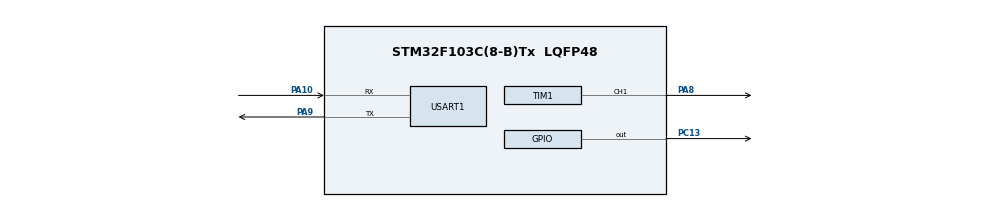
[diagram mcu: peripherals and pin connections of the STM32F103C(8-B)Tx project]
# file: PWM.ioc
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Mcu.Family=STM32F1
Mcu.Name=STM32F103C(8-B)Tx
Mcu.Package=LQFP48
NVIC.PriorityGroup=NVIC_PRIORITYGROUP_4
PA10.Mode=Asynchronous
PA10.Signal=USART1_RX
PA13.Mode=Serial_Wire
PA13.Signal=SYS_JTMS-SWDIO
PA14.Mode=Serial_Wire
PA14.Signal=SYS_JTCK-SWCLK
PA8.Signal=S_TIM1_CH1
PA9.Mode=Asynchronous
PA9.Signal=USART1_TX
PC13-TAMPER-RTC.GPIO_ModeDefaultOutputPP=GPIO_MODE_OUTPUT_OD
PC13-TAMPER-RTC.PinState=GPIO_PIN_SET
PC13-TAMPER-RTC.Signal=GPIO_Output
ProjectManager.HeapSize=0x200
ProjectManager.StackSize=0x400
ProjectManager.TargetToolchain=MDK-ARM V5.32
RCC.APB1Freq_Value=8000000
RCC.APB2Freq_Value=8000000
SH.S_TIM1_CH1.0=TIM1_CH1,PWM Generation1 CH1
TIM1.AutoReloadPreload=TIM_AUTORELOAD_PRELOAD_ENABLE
TIM1.Channel-PWM\ Generation1\ CH1=TIM_CHANNEL_1
TIM1.OCFastMode_PWM-PWM\ Generation1\ CH1=TIM_OCFAST_DISABLE
TIM1.OCMode_PWM-PWM\ Generation1\ CH1=TIM_OCMODE_PWM1
TIM1.OCPolarity_1=TIM_OCPOLARITY_HIGH
TIM1.Period=19999
TIM1.Prescaler=7
TIM1.Pulse-PWM\ Generation1\ CH1=1500
USART1.VirtualMode=VM_ASYNC
VP_TIM1_VS_ClockSourceINT.Mode=Internal
board=custom

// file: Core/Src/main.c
/* USER CODE BEGIN Header */
/**
  ******************************************************************************
  * @file           : main.c
  * @brief          : Main program body
  ******************************************************************************
  * @attention
  *
  * <h2><center>&copy; Copyright (c) 2026 STMicroelectronics.
  * All rights reserved.</center></h2>
  *
  * This software component is licensed by ST under BSD 3-Clause license,
  * the "License"; You may not use this file except in compliance with the
  * License. You may obtain a copy of the License at:
  *                        opensource.org/licenses/BSD-3-Clause
  *
  ******************************************************************************
  */
/* USER CODE END Header */
#include "main.h"

TIM_HandleTypeDef htim1;

UART_HandleTypeDef huart1;

void SystemClock_Config(void);
static void MX_GPIO_Init(void);
static void MX_TIM1_Init(void);
static void MX_USART1_UART_Init(void);

int main(void)
{

  /* MCU Configuration--------------------------------------------------------*/

  /* Reset of all peripherals, Initializes the Flash interface and the Systick. */
  HAL_Init();

  /* Configure the system clock */
  SystemClock_Config();

  /* Initialize all configured peripherals */
  MX_GPIO_Init();
  MX_TIM1_Init();
  MX_USART1_UART_Init();
  /* USER CODE BEGIN 2 */
	/* TIM1 runs at 1 MHz after the prescaler, so compare values are in us. */
	if (HAL_TIM_PWM_Start(&htim1, TIM_CHANNEL_1) != HAL_OK)
	{
	  Error_Handler();
	}
  /* USER CODE END 2 */

  /* Infinite loop */
  /* USER CODE BEGIN WHILE */
	while (1)
	{
		/* 0 -> 90 -> 180 degrees, one second at each position. */
		__HAL_TIM_SET_COMPARE(&htim1, TIM_CHANNEL_1, 1000);   /* 0 degrees */
		HAL_Delay(2000);

		__HAL_TIM_SET_COMPARE(&htim1, TIM_CHANNEL_1, 1500);  /* 90 degrees */
		HAL_Delay(2000);

		__HAL_TIM_SET_COMPARE(&htim1, TIM_CHANNEL_1, 2000);  /* 180 degrees */
		HAL_Delay(2000);
    /* USER CODE END WHILE */

	}
}

void SystemClock_Config(void)
{
  RCC_OscInitTypeDef RCC_OscInitStruct = {0};
  RCC_ClkInitTypeDef RCC_ClkInitStruct = {0};

  /** Initializes the RCC Oscillators according to the specified parameters
  * in the RCC_OscInitTypeDef structure.
  */
  RCC_OscInitStruct.OscillatorType = RCC_OSCILLATORTYPE_HSI;
  RCC_OscInitStruct.HSIState = RCC_HSI_ON;
  RCC_OscInitStruct.HSICalibrationValue = RCC_HSICALIBRATION_DEFAULT;
  RCC_OscInitStruct.PLL.PLLState = RCC_PLL_NONE;
  if (HAL_RCC_OscConfig(&RCC_OscInitStruct) != HAL_OK)
  {
    Error_Handler();
  }
  /** Initializes the CPU, AHB and APB buses clocks
  */
  RCC_ClkInitStruct.ClockType = RCC_CLOCKTYPE_HCLK|RCC_CLOCKTYPE_SYSCLK
                              |RCC_CLOCKTYPE_PCLK1|RCC_CLOCKTYPE_PCLK2;
  RCC_ClkInitStruct.SYSCLKSource = RCC_SYSCLKSOURCE_HSI;
  RCC_ClkInitStruct.AHBCLKDivider = RCC_SYSCLK_DIV1;
  RCC_ClkInitStruct.APB1CLKDivider = RCC_HCLK_DIV1;
  RCC_ClkInitStruct.APB2CLKDivider = RCC_HCLK_DIV1;

  if (HAL_RCC_ClockConfig(&RCC_ClkInitStruct, FLASH_LATENCY_0) != HAL_OK)
  {
    Error_Handler();
  }
}

static void MX_TIM1_Init(void)
{

  TIM_ClockConfigTypeDef sClockSourceConfig = {0};
  TIM_MasterConfigTypeDef sMasterConfig = {0};
  TIM_OC_InitTypeDef sConfigOC = {0};
  TIM_BreakDeadTimeConfigTypeDef sBreakDeadTimeConfig = {0};

  htim1.Instance = TIM1;
  /* HSI is 8 MHz. Divide by 8 to get a 1 MHz timer clock (1 us/tick). */
  htim1.Init.Prescaler = 7;
  htim1.Init.CounterMode = TIM_COUNTERMODE_UP;
  htim1.Init.Period = 19999;
  htim1.Init.ClockDivision = TIM_CLOCKDIVISION_DIV1;
  htim1.Init.RepetitionCounter = 0;
  htim1.Init.AutoReloadPreload = TIM_AUTORELOAD_PRELOAD_ENABLE;
  if (HAL_TIM_Base_Init(&htim1) != HAL_OK)
  {
    Error_Handler();
  }
  sClockSourceConfig.ClockSource = TIM_CLOCKSOURCE_INTERNAL;
  if (HAL_TIM_ConfigClockSource(&htim1, &sClockSourceConfig) != HAL_OK)
  {
    Error_Handler();
  }
  if (HAL_TIM_PWM_Init(&htim1) != HAL_OK)
  {
    Error_Handler();
  }
  sMasterConfig.MasterOutputTrigger = TIM_TRGO_RESET;
  sMasterConfig.MasterSlaveMode = TIM_MASTERSLAVEMODE_DISABLE;
  if (HAL_TIMEx_MasterConfigSynchronization(&htim1, &sMasterConfig) != HAL_OK)
  {
    Error_Handler();
  }
  sConfigOC.OCMode = TIM_OCMODE_PWM1;
  sConfigOC.Pulse = 1500;
  sConfigOC.OCPolarity = TIM_OCPOLARITY_HIGH;
  sConfigOC.OCNPolarity = TIM_OCNPOLARITY_HIGH;
  sConfigOC.OCFastMode = TIM_OCFAST_DISABLE;
  sConfigOC.OCIdleState = TIM_OCIDLESTATE_RESET;
  sConfigOC.OCNIdleState = TIM_OCNIDLESTATE_RESET;
  if (HAL_TIM_PWM_ConfigChannel(&htim1, &sConfigOC, TIM_CHANNEL_1) != HAL_OK)
  {
    Error_Handler();
  }
  sBreakDeadTimeConfig.OffStateRunMode = TIM_OSSR_DISABLE;
  sBreakDeadTimeConfig.OffStateIDLEMode = TIM_OSSI_DISABLE;
  sBreakDeadTimeConfig.LockLevel = TIM_LOCKLEVEL_OFF;
  sBreakDeadTimeConfig.DeadTime = 0;
  sBreakDeadTimeConfig.BreakState = TIM_BREAK_DISABLE;
  sBreakDeadTimeConfig.BreakPolarity = TIM_BREAKPOLARITY_HIGH;
  sBreakDeadTimeConfig.AutomaticOutput = TIM_AUTOMATICOUTPUT_DISABLE;
  if (HAL_TIMEx_ConfigBreakDeadTime(&htim1, &sBreakDeadTimeConfig) != HAL_OK)
  {
    Error_Handler();
  }
  HAL_TIM_MspPostInit(&htim1);

}

static void MX_USART1_UART_Init(void)
{

  huart1.Instance = USART1;
  huart1.Init.BaudRate = 115200;
  huart1.Init.WordLength = UART_WORDLENGTH_8B;
  huart1.Init.StopBits = UART_STOPBITS_1;
  huart1.Init.Parity = UART_PARITY_NONE;
  huart1.Init.Mode = UART_MODE_TX_RX;
  huart1.Init.HwFlowCtl = UART_HWCONTROL_NONE;
  huart1.Init.OverSampling = UART_OVERSAMPLING_16;
  if (HAL_UART_Init(&huart1) != HAL_OK)
  {
    Error_Handler();
  }

}

static void MX_GPIO_Init(void)
{
  GPIO_InitTypeDef GPIO_InitStruct = {0};

  /* GPIO Ports Clock Enable */
  __HAL_RCC_GPIOC_CLK_ENABLE();
  __HAL_RCC_GPIOA_CLK_ENABLE();

  /*Configure GPIO pin Output Level */
  HAL_GPIO_WritePin(GPIOC, GPIO_PIN_13, GPIO_PIN_SET);

  /*Configure GPIO pin : PC13 */
  GPIO_InitStruct.Pin = GPIO_PIN_13;
  GPIO_InitStruct.Mode = GPIO_MODE_OUTPUT_OD;
  GPIO_InitStruct.Pull = GPIO_NOPULL;
  GPIO_InitStruct.Speed = GPIO_SPEED_FREQ_LOW;
  HAL_GPIO_Init(GPIOC, &GPIO_InitStruct);

}

void Error_Handler(void)
{
  __disable_irq();
  while (1)
  {
  }
}

/************************ (C) COPYRIGHT STMicroelectronics *****END OF FILE****/
